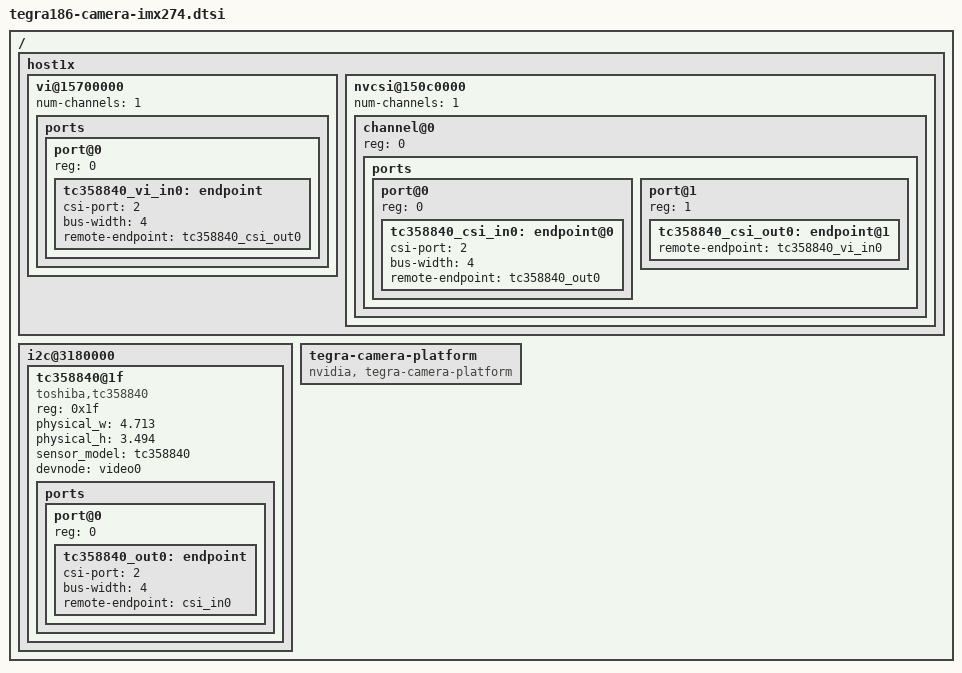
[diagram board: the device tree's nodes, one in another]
/*
 * Copyright (c) 2015-2016, NVIDIA CORPORATION.  All rights reserved.
 *
 * This program is free software; you can redistribute it and/or modify
 * it under the terms of the GNU General Public License as published by
 * the Free Software Foundation; either version 2 of the License, or
 * (at your option) any later version.
 *
 * This program is distributed in the hope that it will be useful, but WITHOUT
 * ANY WARRANTY; without even the implied warranty of MERCHANTABILITY or
 * FITNESS FOR A PARTICULAR PURPOSE.  See the GNU General Public License for
 * more details.
 *
 * You should have received a copy of the GNU General Public License
 * along with this program.  If not, see <http://www.gnu.org/licenses/>.
 */

#include <dt-bindings/media/camera.h>
#include <dt-bindings/platform/t210/t210.h>

/ {
	host1x {
		vi@15700000 {
			num-channels = <1>;
			ports {
				#address-cells = <1>;
				#size-cells = <0>;
				port@0 {
					reg = <0>;
					tc358840_vi_in0: endpoint {
						csi-port = <2>;
						bus-width = <4>;
						remote-endpoint = <&tc358840_csi_out0>;
					};
				};
			};
		};

		nvcsi@150c0000 {
			num-channels = <1>;
			channel@0 {
				reg = <0>;
				ports {
					#address-cells = <1>;
					#size-cells = <0>;
					port@0 {
						reg = <0>;
						tc358840_csi_in0: endpoint@0 {
							csi-port = <2>;
							bus-width = <4>;
							remote-endpoint = <&tc358840_out0>;
						};
					};
					port@1 {
						reg = <1>;
						tc358840_csi_out0: endpoint@1 {
							remote-endpoint = <&tc358840_vi_in0>;
						};
					};
				};
			};
		};
	};
	i2c@3180000 {
		tc358840@1f {
			compatible = "toshiba,tc358840";

			reg = <0x1f>;
			/* Physical dimensions of sensor */
			physical_w = "4.713";
			physical_h = "3.494";

			/* Sensor Model */
			sensor_model ="tc358840";
			devnode ="video0";
			ports {
				#address-cells = <1>;
				#size-cells = <0>;

				port@0 {
					reg = <0>;
					tc358840_out0: endpoint {
						csi-port = <2>;
						bus-width = <4>;
						remote-endpoint = <&csi_in0>;
					};
				};
			};
		};
	};

	tegra-camera-platform {
		compatible = "nvidia, tegra-camera-platform";
	};
};
